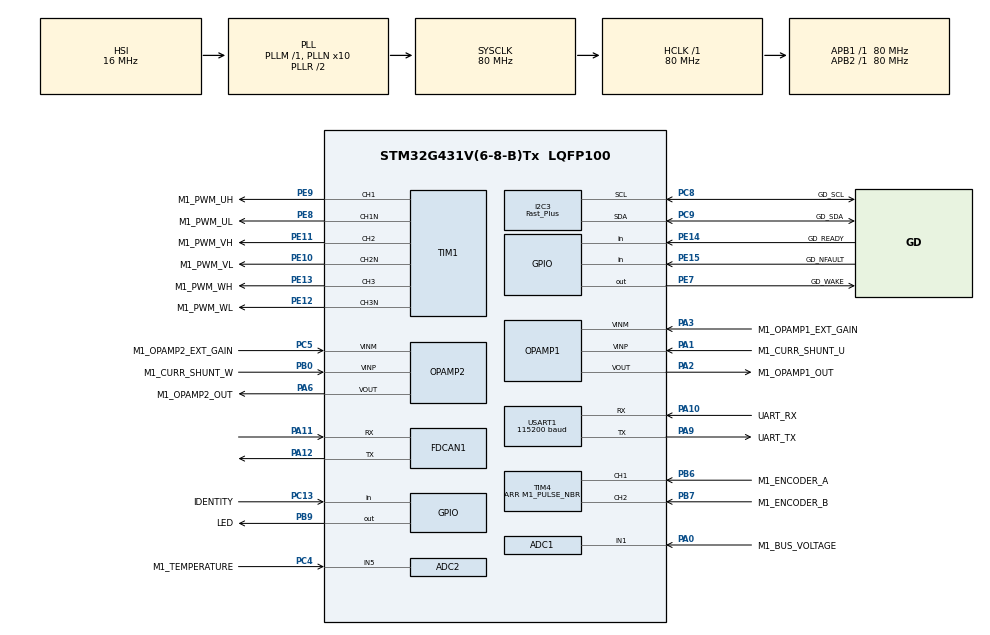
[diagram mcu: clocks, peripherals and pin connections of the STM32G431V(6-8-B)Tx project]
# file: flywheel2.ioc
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ADC1.Channel-1\#ChannelRegularConversion=ADC_CHANNEL_1
ADC1.ClockPrescaler=ADC_CLOCK_ASYNC_DIV1
ADC1.ContinuousConvMode=DISABLE
ADC1.DMAContinuousRequests=DISABLE
ADC1.DataAlign=ADC_DATAALIGN_LEFT
ADC1.DiscontinuousConvMode=DISABLE
ADC1.EOCSelection=ADC_EOC_SINGLE_CONV
ADC1.EnableAnalogWatchDog1=false
ADC1.EnableAnalogWatchDog2=false
ADC1.EnableAnalogWatchDog3=false
ADC1.EnableInjectedConversion=ENABLE
ADC1.EnableRegularConversion=ENABLE
ADC1.ExternalTrigConv=ADC_SOFTWARE_START
ADC1.ExternalTrigConvEdge=ADC_EXTERNALTRIGCONVEDGE_NONE
ADC1.ExternalTrigInjecConv=ADC_EXTERNALTRIGINJEC_T1_TRGO
ADC1.ExternalTrigInjecConvEdge=ADC_EXTERNALTRIGINJECCONV_EDGE_RISING
ADC1.InjNumberOfConversion=1
ADC1.InjectedChannel-1\#ChannelInjectedConversion=ADC_CHANNEL_3
ADC1.InjectedConvMode=None
ADC1.InjectedOffset-1\#ChannelInjectedConversion=0
ADC1.InjectedOffsetNumber-1\#ChannelInjectedConversion=ADC_OFFSET_NONE
ADC1.InjectedRank-1\#ChannelInjectedConversion=1
ADC1.InjectedSamplingTime-1\#ChannelInjectedConversion=ADC_SAMPLETIME_6CYCLES_5
ADC1.LowPowerAutoWait=DISABLE
ADC1.NbrOfConversion=1
ADC1.NbrOfConversionFlag=1
ADC1.Offset-1\#ChannelRegularConversion=0
ADC1.OffsetNumber-1\#ChannelRegularConversion=ADC_OFFSET_NONE
ADC1.Overrun=ADC_OVR_DATA_PRESERVED
ADC1.Rank-1\#ChannelRegularConversion=1
ADC1.Resolution=ADC_RESOLUTION_12B
ADC1.SamplingTime-1\#ChannelRegularConversion=ADC_SAMPLETIME_47CYCLES_5
ADC1.ScanConvMode=ADC_SCAN_DISABLE
ADC1.master=1
ADC2.Channel-1\#ChannelRegularConversion=ADC_CHANNEL_5
ADC2.ClockPrescaler=ADC_CLOCK_ASYNC_DIV1
ADC2.ContinuousConvMode=DISABLE
ADC2.DMAContinuousRequests=DISABLE
ADC2.DataAlign=ADC_DATAALIGN_LEFT
ADC2.DiscontinuousConvMode=DISABLE
ADC2.EOCSelection=ADC_EOC_SINGLE_CONV
ADC2.EnableAnalogWatchDog1=false
ADC2.EnableAnalogWatchDog2=false
ADC2.EnableAnalogWatchDog3=false
ADC2.EnableInjectedConversion=ENABLE
ADC2.EnableRegularConversion=ENABLE
ADC2.ExternalTrigConv=ADC_SOFTWARE_START
ADC2.ExternalTrigConvEdge=ADC_EXTERNALTRIGCONVEDGE_NONE
ADC2.ExternalTrigInjecConv=ADC_EXTERNALTRIGINJEC_T1_TRGO
ADC2.ExternalTrigInjecConvEdge=ADC_EXTERNALTRIGINJECCONV_EDGE_RISING
ADC2.InjNumberOfConversion=1
ADC2.InjectedChannel-1\#ChannelInjectedConversion=ADC_CHANNEL_3
ADC2.InjectedConvMode=None
ADC2.InjectedOffset-1\#ChannelInjectedConversion=0
ADC2.InjectedOffsetNumber-1\#ChannelInjectedConversion=ADC_OFFSET_NONE
ADC2.InjectedRank-1\#ChannelInjectedConversion=1
ADC2.InjectedSamplingTime-1\#ChannelInjectedConversion=ADC_SAMPLETIME_6CYCLES_5
ADC2.LowPowerAutoWait=DISABLE
ADC2.NbrOfConversion=1
ADC2.NbrOfConversionFlag=1
ADC2.Offset-1\#ChannelRegularConversion=0
ADC2.OffsetNumber-1\#ChannelRegularConversion=ADC_OFFSET_NONE
ADC2.Overrun=ADC_OVR_DATA_PRESERVED
ADC2.Rank-1\#ChannelRegularConversion=1
ADC2.Resolution=ADC_RESOLUTION_12B
ADC2.SamplingTime-1\#ChannelRegularConversion=ADC_SAMPLETIME_47CYCLES_5
ADC2.ScanConvMode=ADC_SCAN_DISABLE
ADC2.master=1
Dma.Request0=USART1_RX
Dma.Request1=USART1_TX
Dma.USART1_RX.0.Direction=DMA_PERIPH_TO_MEMORY
Dma.USART1_RX.0.EventEnable=DISABLE
Dma.USART1_RX.0.Instance=DMA1_Channel1
Dma.USART1_RX.0.MemDataAlignment=DMA_MDATAALIGN_BYTE
Dma.USART1_RX.0.MemInc=DMA_MINC_ENABLE
Dma.USART1_RX.0.Mode=DMA_NORMAL
Dma.USART1_RX.0.PeriphDataAlignment=DMA_PDATAALIGN_BYTE
Dma.USART1_RX.0.PeriphInc=DMA_PINC_DISABLE
Dma.USART1_RX.0.Polarity=HAL_DMAMUX_REQ_GEN_RISING
Dma.USART1_RX.0.Priority=DMA_PRIORITY_LOW
Dma.USART1_RX.0.RequestNumber=1
Dma.USART1_RX.0.SignalID=NONE
Dma.USART1_RX.0.SyncEnable=DISABLE
Dma.USART1_RX.0.SyncPolarity=HAL_DMAMUX_SYNC_NO_EVENT
Dma.USART1_RX.0.SyncRequestNumber=1
Dma.USART1_RX.0.SyncSignalID=NONE
Dma.USART1_TX.1.Direction=DMA_MEMORY_TO_PERIPH
Dma.USART1_TX.1.EventEnable=DISABLE
Dma.USART1_TX.1.Instance=DMA1_Channel2
Dma.USART1_TX.1.MemDataAlignment=DMA_MDATAALIGN_BYTE
Dma.USART1_TX.1.MemInc=DMA_MINC_ENABLE
Dma.USART1_TX.1.Mode=DMA_NORMAL
Dma.USART1_TX.1.PeriphDataAlignment=DMA_PDATAALIGN_BYTE
Dma.USART1_TX.1.PeriphInc=DMA_PINC_DISABLE
Dma.USART1_TX.1.Polarity=HAL_DMAMUX_REQ_GEN_RISING
Dma.USART1_TX.1.Priority=DMA_PRIORITY_LOW
Dma.USART1_TX.1.RequestNumber=1
Dma.USART1_TX.1.SignalID=NONE
Dma.USART1_TX.1.SyncEnable=DISABLE
Dma.USART1_TX.1.SyncPolarity=HAL_DMAMUX_SYNC_NO_EVENT
Dma.USART1_TX.1.SyncRequestNumber=1
Dma.USART1_TX.1.SyncSignalID=NONE
ExtraMW=MotorControl
ExtraMW.MotorControl.Config=MotorControl
ExtraMW.MotorControl.Mode=MotorControl
ExtraMW.MotorControl.Root=MCSDK_v6.4.1-Full/MotorControl
ExtraMW.MotorControl.Template=templates
FDCAN1.CalculateBaudRateNominal=1000000
FDCAN1.CalculateTimeBitNominal=1000
FDCAN1.CalculateTimeQuantumNominal=62.5
FDCAN1.NominalPrescaler=5
FDCAN1.NominalTimeSeg1=12
FDCAN1.NominalTimeSeg2=3
I2C3.I2C_Speed_Mode=I2C_Fast_Plus
I2C3.Timing=0x00B10E24
Mcu.Family=STM32G4
Mcu.Name=STM32G431V(6-8-B)Tx
Mcu.Package=LQFP100
MotorControl.ADC_1_PERIPH=ADC1
MotorControl.ADC_2_PERIPH=ADC2
MotorControl.ADC_AHBPERIPH=RCC_AHBPeriph_ADC12
MotorControl.ADC_CLOCK_WB_DIV=1
MotorControl.ADC_PERIPH=ADC1
MotorControl.ADC_REFERENCE_VOLTAGE=3.3
MotorControl.BOARD=Jame_driver_v2
MotorControl.BUS_VOLTAGE_READING=true
MotorControl.CCMRAM_ENABLED=false
MotorControl.CLOCK_FREQUENCY=CPU_CLK_170_MHZ
MotorControl.CLOCK_SOURCE=INTERNAL
MotorControl.CPU_CLK_170_MHZ=true
MotorControl.CTLBOARD_NAME=Jame_driver_v2
MotorControl.CUBE_MX_VER=6.16.1
MotorControl.CURRENT_READING_TOPOLOGY=THREE_SHUNT_INDEPENDENT_RESOURCES
MotorControl.CURR_SAMPLING_TIME=6
MotorControl.DBG_MCU_LOAD_MEASURE=false
MotorControl.DEBUG_DAC_FUNCTIONALITY_EN=false
MotorControl.DRIVES_NUMBER_SELECTION=SINGLEDRIVE
MotorControl.DRIVE_NUMBER=1
MotorControl.DRIVE_TYPE=FOC
MotorControl.ENCODER=true
MotorControl.ENCODER_AVAILABLE=true
MotorControl.ENCODER_PPR=1024
MotorControl.ENC_A_GPIO_PIN=LL_GPIO_PIN_6
MotorControl.ENC_A_GPIO_PORT=GPIOB
MotorControl.ENC_B_GPIO_PIN=LL_GPIO_PIN_7
MotorControl.ENC_B_GPIO_PORT=GPIOB
MotorControl.ENC_ICx_FILTER=119
MotorControl.ENC_INVERT_SPEED=true
MotorControl.ENC_TIMER_SELECTION=ENC_TIM4
MotorControl.ENC_USE_CH3=false
MotorControl.EXT_CLOCK_FREQUENCY=INT_RC_OSC
MotorControl.FEEDBACK_NET_FILTERING=false
MotorControl.FLASH_SIZE=128
MotorControl.HALL_SENSORS_AVAILABLE=false
MotorControl.HIGH_SIDE_IDLE_STATE=false
MotorControl.HWV_CS=ThreeShunt_RawCurrents_SingleEnded_ExternalGain
MotorControl.HWV_PWM=PoweringHighAndLowSides
MotorControl.HW_COMPLEMENTED_LOW_SIDE=false
MotorControl.HW_DEAD_TIME_NS=750
MotorControl.INT_RC_OSC=true
MotorControl.IPs=I2C3,CORDIC,SYS,NVIC,RCC,MotorControl,TIM1,OPAMP1,OPAMP2,ADC1,ADC2,TIM4,USART1,DMA
MotorControl.LOW_MEMORY_FOOTPRINT_REG=false
MotorControl.LOW_SIDE_IDLE_STATE=false
MotorControl.LOW_SIDE_SIGNALS_ENABLING=LS_PWM_TIMER
MotorControl.M1_ALIGNMENT_ANGLE_DEG=90
MotorControl.M1_ALIGNMENT_DURATION=1200
MotorControl.M1_AMPLIFICATION_GAIN=7.33
MotorControl.M1_ANGC={0,0,0,0,0,0,0,0}
MotorControl.M1_AUXILIARY_SPEED_SENSOR=NONE
MotorControl.M1_BOARD_MAX_CURRENT=43.3
MotorControl.M1_BUS_VOLTAGE_READING=true
MotorControl.M1_COMMUTATION_STEP_TIME_BUF_SIZE=12
MotorControl.M1_CONSTANT1_D=49154
MotorControl.M1_CONSTANT1_Q=49154
MotorControl.M1_CONSTANT2_QD=4907
MotorControl.M1_CS_ADC_NUM=2
MotorControl.M1_CS_ADC_PHASE_SHARED=NONE
MotorControl.M1_CS_ADC_U=ADC1
MotorControl.M1_CS_ADC_W=ADC2
MotorControl.M1_CS_CHANNEL_U=3
MotorControl.M1_CS_CHANNEL_W=3
MotorControl.M1_CS_OPAMP_DYNAMIC_OUTPUT_SWITCH=false
MotorControl.M1_CS_OPAMP_NUM=2
MotorControl.M1_CS_OPAMP_PHASE_SHARED=V
MotorControl.M1_CS_OPAMP_U=OPAMP1
MotorControl.M1_CS_OPAMP_VPSEL_U=PA1
MotorControl.M1_CS_OPAMP_VPSEL_V=PA7
MotorControl.M1_CS_OPAMP_VPSEL_W=PB0
MotorControl.M1_CS_OPAMP_W=OPAMP2
MotorControl.M1_CURRENT_AMPLIFICATION_TOPO=INT_SINGLE_ENDED
MotorControl.M1_CURRENT_SENSING_TOPO=THREE_SHUNT
MotorControl.M1_CURR_SAMPLING_TIME=6
MotorControl.M1_DBG_OPEN_LOOP_ENABLE=true
MotorControl.M1_DC_CURRENT_RS_MEAS=43.3
MotorControl.M1_DEFAULT_CONTROL_MODE=STC_SPEED_MODE
MotorControl.M1_DEFAULT_FLUX_COMPONENT=0
MotorControl.M1_DEFAULT_TARGET_SPEED_RPM=5400
MotorControl.M1_DEFAULT_TORQUE_COMPONENT=0
MotorControl.M1_DISCONTINUOUS_PWM=false
MotorControl.M1_DP_TOPOLOGY=NONE
MotorControl.M1_DRIVE_TYPE=FOC
MotorControl.M1_ENCODER_PPR=1024
MotorControl.M1_ENC_AVERAGING_FIFO_DEPTH=16
MotorControl.M1_ENC_A_GPIO_PIN=LL_GPIO_PIN_6
MotorControl.M1_ENC_A_GPIO_PORT=GPIOB
MotorControl.M1_ENC_B_GPIO_PIN=LL_GPIO_PIN_7
MotorControl.M1_ENC_B_GPIO_PORT=GPIOB
MotorControl.M1_ENC_ICx_FILTER=119
MotorControl.M1_ENC_TIMER_IRQ=TIM4
MotorControl.M1_ENC_TIMER_SELECTION=ENC_TIM4
MotorControl.M1_ENC_USE_CH3=false
MotorControl.M1_FEED_FORWARD_CURRENT_REG_ENABLING=false
MotorControl.M1_FINAL_I_ALIGNMENT=20
MotorControl.M1_FLUX_WEAKENING_ENABLING=false
MotorControl.M1_FW_KIDIV=32768
MotorControl.M1_FW_KI_GAIN=5000
MotorControl.M1_FW_KPDIV=32768
MotorControl.M1_FW_KP_GAIN=3000
MotorControl.M1_FW_VOLTAGE_REF=985
MotorControl.M1_HALL_PHASE_SHIFT=300
MotorControl.M1_HALL_SENSORS_PLACEMENT=DEGREES_120
MotorControl.M1_HIGH_SIDE_IDLE_STATE=false
MotorControl.M1_HW_DEAD_TIME_NS=750
MotorControl.M1_ICL_ENABLED=false
MotorControl.M1_ID_DEMAG=-43.3
MotorControl.M1_INT_AMP_OPAMP1_PIN=[{'mode'\:'Standalone','name'\:'PA1','signal'\:'OPAMP1_VINP','label'\:'SHUNT_P_U'},{'mode'\:'Standalone','name'\:'PA3','signal'\:'OPAMP1_VINM','label'\:'CURR_AMP_U'},{'mode'\:'Standalone','name'\:'PA2','signal'\:'OPAMP1_VOUT','label'\:'CURR_AMP_U'},{'mode'\:'Standalone','name'\:'PA7','signal'\:'OPAMP1_VINP','label'\:'SHUNT_P_V'},{'mode'\:'Standalone','name'\:'PC5','signal'\:'OPAMP1_VINM','label'\:'CURR_AMP_V'},{'mode'\:'Standalone','name'\:'PA2','signal'\:'OPAMP1_VOUT','label'\:'CURR_AMP_V'}]
MotorControl.M1_INT_AMP_OPAMP2_PIN=[{'mode'\:'Standalone','name'\:'PB0','signal'\:'OPAMP2_VINP','label'\:'SHUNT_P_W'},{'mode'\:'Standalone','name'\:'PC5','signal'\:'OPAMP2_VINM','label'\:'CURR_AMP_W'},{'mode'\:'Standalone','name'\:'PA6','signal'\:'OPAMP2_VOUT','label'\:'CURR_AMP_W'},{'mode'\:'Standalone','name'\:'PA7','signal'\:'OPAMP2_VINP','label'\:'SHUNT_P_V'},{'mode'\:'Standalone','name'\:'PC5','signal'\:'OPAMP2_VINM','label'\:'CURR_AMP_V'},{'mode'\:'Standalone','name'\:'PA6','signal'\:'OPAMP2_VOUT','label'\:'CURR_AMP_V'}]
MotorControl.M1_INT_AMP_OPAMPS=['OPAMP1','OPAMP2']
MotorControl.M1_IQMAX=43.3
MotorControl.M1_LDLQ_RATIO=1.000
MotorControl.M1_LOW_SIDE_IDLE_STATE=false
MotorControl.M1_LOW_SIDE_SIGNALS_ENABLING=LS_PWM_TIMER
MotorControl.M1_LS=0.00007
MotorControl.M1_MAX_APPLICATION_SPEED=15000
MotorControl.M1_MAX_MODULATION_INDEX=100
MotorControl.M1_MIN_APPLICATION_SPEED=0
MotorControl.M1_MOTOR_MAX_SPEED_RPM=15000
MotorControl.M1_MOTOR_NAME=ILM38x06 Star Parrellel
MotorControl.M1_MOTOR_RATED_FLUX=0.007908353
MotorControl.M1_MOTOR_VOLTAGE_CONSTANT=1.1
MotorControl.M1_MTPA_ENABLING=false
MotorControl.M1_NOMINAL_BUS_VOLTAGE_V=33
MotorControl.M1_NOMINAL_CURRENT=43.3
MotorControl.M1_OCP_TOPOLOGY=NONE
MotorControl.M1_OFST={0,0,0,0,0,0,0,0}
MotorControl.M1_ON_OVER_VOLTAGE=TURN_OFF_PWM
MotorControl.M1_OVERMODULATION=false
MotorControl.M1_OVP_THRESHOLD_HIGH=33
MotorControl.M1_OV_TEMPERATURE_PROT_ENABLING=false
MotorControl.M1_OV_VOLTAGE_PROT_ENABLING=true
MotorControl.M1_OV_VOLTAGE_THRESHOLD_V=33
MotorControl.M1_PID_FLUX_KD_DEFAULT=100
MotorControl.M1_PID_FLUX_KI_DEFAULT=754
MotorControl.M1_PID_FLUX_KP_DEFAULT=2347
MotorControl.M1_PID_SPEED_KD_DEFAULT=0
MotorControl.M1_PID_SPEED_KI_DEFAULT=52
MotorControl.M1_PID_SPEED_KP_DEFAULT=3646
MotorControl.M1_PID_TORQUE_KD_DEFAULT=100
MotorControl.M1_PID_TORQUE_KI_DEFAULT=754
MotorControl.M1_PID_TORQUE_KP_DEFAULT=2347
MotorControl.M1_POLE_PAIR_NUM=7
MotorControl.M1_POSITION_CTRL_ENABLING=false
MotorControl.M1_POTENTIOMETER_ENABLE=false
MotorControl.M1_POWERBOARD_NAME=Jame_driver_v2
MotorControl.M1_PWM_CHARGE_BOOT_CAP_DUTY_CYCLES=0.000
MotorControl.M1_PWM_CHARGE_BOOT_CAP_MS=10
MotorControl.M1_PWM_DRIVER_PN=NTMFSC1D0N04HL
MotorControl.M1_PWM_FREQUENCY=16000
MotorControl.M1_PWM_TIMER_BRK_IRQ=TIM1_BRK_TIM15
MotorControl.M1_PWM_TIMER_SELECTION=PWM_TIM1
MotorControl.M1_PWM_TIMER_UP_IRQ=TIM1_UP_TIM16
MotorControl.M1_REGULATION_EXECUTION_RATE=1
MotorControl.M1_RS=0.09
MotorControl.M1_RSHUNT=0.01
MotorControl.M1_SEGDIV=0
MotorControl.M1_SHARED_SIGNAL_ENABLE=false
MotorControl.M1_SPD_DIFFERENTIAL_TERM_ENABLING=false
MotorControl.M1_SPEED_LOOP_FREQUENCY_HZ=1000
MotorControl.M1_SPEED_SENSOR=QUAD_ENCODER
MotorControl.M1_SP_KDDIV=16
MotorControl.M1_SP_KIDIV=16384
MotorControl.M1_SP_KPDIV=1024
MotorControl.M1_SS_MEAS_ERRORS_BEFORE_FAULTS=3
MotorControl.M1_SW_DEADTIME_NS=575
MotorControl.M1_T0_C=50
MotorControl.M1_TEMPERATURE_READING=true
MotorControl.M1_TEMP_ADC_SAMPLING_TIME=47
MotorControl.M1_TEMP_FDBK_ADC=ADC2
MotorControl.M1_TEMP_FDBK_CHANNEL=ADC_CHANNEL_5
MotorControl.M1_TF_KDDIV=8192
MotorControl.M1_TF_KIDIV=16384
MotorControl.M1_TF_KPDIV=4096
MotorControl.M1_TNOISE_NS=150
MotorControl.M1_TRISE_NS=61
MotorControl.M1_T_MAX=100
MotorControl.M1_UD_VOLTAGE_THRESHOLD_V=1
MotorControl.M1_USE_INTERNAL_OPAMP=true
MotorControl.M1_UV_VOLTAGE_PROT_ENABLING=true
MotorControl.M1_V0_V=1.75
MotorControl.M1_VBUS_ADC=ADC1
MotorControl.M1_VBUS_ADC_SAMPLING_TIME=47
MotorControl.M1_VBUS_CHANNEL=ADC_CHANNEL_1
MotorControl.M1_VBUS_PARTITIONING_FACTOR=0.0625
MotorControl.M1_dV_dT=0.025
MotorControl.MAX_READABLE_CURRENT=22.51
MotorControl.MCPA_OVER_UART_A_STREAM=10
MotorControl.MCP_ASPEP_OVER_UART=true
MotorControl.MCP_ASYNC_EN=true
MotorControl.MCP_ASYNC_OVER_ASPEP_EN=true
MotorControl.MCP_ASYNC_OVER_UART_A_EN=true
MotorControl.MCP_DMACH_RX_UART_A=1
MotorControl.MCP_DMACH_TX_UART_A=2
MotorControl.MCP_DMA_RX_UART_A=DMA1
MotorControl.MCP_DMA_TX_UART_A=DMA1
MotorControl.MCP_EN=true
MotorControl.MCP_IRQ_HANDLER_DMA_RX_UART_A=DMA1_Channel1_IRQHandler
MotorControl.MCP_IRQ_HANDLER_UART_A=USART1_IRQHandler
MotorControl.MCP_OVER_ASPEP_EN=true
MotorControl.MCP_OVER_STLNK_EN=false
MotorControl.MCP_OVER_UART_A_EN=true
MotorControl.MCP_OVER_UART_B_EN=false
MotorControl.MCP_RX_SYNC_PAYLOAD_MAX=256
MotorControl.MCP_TX_ASYNC_PAYLOAD_MAX_UART_A=2048
MotorControl.MCP_TX_SYNC_PAYLOAD_MAX=256
MotorControl.MCU=STSPIN32G4
MotorControl.MCU_FAMILY=STM32G4
MotorControl.MCU_LINE=STM32G4x1
MotorControl.MCU_NAME=STM32G431V(6-8-B)Tx
MotorControl.MCU_PACKAGE=LQFP100
MotorControl.MCU_TYPE=STSPIN32G4
MotorControl.MCU_USERNAME=STM32G431VBTx
MotorControl.MC_WORKBENCH_VERSION=6.4.1
MotorControl.MOTOR_PROFILER=false
MotorControl.MOTOR_TYPE=PMSM
MotorControl.ON_OVER_VOLTAGE=TURN_OFF_PWM
MotorControl.OPAMP1_INVERTINGINPUT=OPAMP1_InvertingInput_PA3
MotorControl.OPAMP1_INVERTINGINPUT_GPIO_PIN=LL_GPIO_PIN_3
MotorControl.OPAMP1_INVERTINGINPUT_GPIO_PORT=GPIOA
MotorControl.OPAMP1_INVERTINGINPUT_MODE=EXT_MODE
MotorControl.OPAMP1_NONINVERTINGINPUT_PHA=OPAMP1_NonInvertingInput_PA1
MotorControl.OPAMP1_NONINVERTINGINPUT_PHA_GPIO_PIN=LL_GPIO_PIN_1
MotorControl.OPAMP1_NONINVERTINGINPUT_PHA_GPIO_PORT=GPIOA
MotorControl.OPAMP1_NONINVERTINGINPUT_PHB=OPAMP1_NonInvertingInput_PA7
MotorControl.OPAMP1_NONINVERTINGINPUT_PHB_GPIO_PIN=LL_GPIO_PIN_7
MotorControl.OPAMP1_NONINVERTINGINPUT_PHB_GPIO_PORT=GPIOA
MotorControl.OPAMP1_OUT_GPIO_PIN=LL_GPIO_PIN_2
MotorControl.OPAMP1_OUT_GPIO_PORT=GPIOA
MotorControl.OPAMP1_SELECTION=OPAMP1
MotorControl.OPAMP2_INVERTINGINPUT=OPAMP2_InvertingInput_PC5
MotorControl.OPAMP2_INVERTINGINPUT_GPIO_PIN=LL_GPIO_PIN_5
MotorControl.OPAMP2_INVERTINGINPUT_GPIO_PORT=GPIOC
MotorControl.OPAMP2_INVERTINGINPUT_MODE=EXT_MODE
MotorControl.OPAMP2_NONINVERTINGINPUT_PHB=OPAMP2_NonInvertingInput_PA7
MotorControl.OPAMP2_NONINVERTINGINPUT_PHB_GPIO_PIN=LL_GPIO_PIN_7
MotorControl.OPAMP2_NONINVERTINGINPUT_PHB_GPIO_PORT=GPIOA
MotorControl.OPAMP2_NONINVERTINGINPUT_PHC=OPAMP2_NonInvertingInput_PB0
MotorControl.OPAMP2_NONINVERTINGINPUT_PHC_GPIO_PIN=LL_GPIO_PIN_0
MotorControl.OPAMP2_NONINVERTINGINPUT_PHC_GPIO_PORT=GPIOB
MotorControl.OPAMP2_OUT_GPIO_PIN=LL_GPIO_PIN_6
MotorControl.OPAMP2_OUT_GPIO_PORT=GPIOA
MotorControl.OPAMP2_SELECTION=OPAMP2
MotorControl.OPAMP_PGAGAIN=OPAMP_OPAMP_PGAGain_16
MotorControl.OPAMP_TYPE_GAIN=EXTERNAL
MotorControl.OV_TEMPERATURE_PROT_ENABLING=false
MotorControl.OV_VOLTAGE_PROT_ENABLING=true
MotorControl.PHASE_UH_GPIO_PIN=LL_GPIO_PIN_9
MotorControl.PHASE_UH_GPIO_PORT=GPIOE
MotorControl.PHASE_UH_POLARITY=H_ACTIVE_HIGH
MotorControl.PHASE_UL_GPIO_PIN=LL_GPIO_PIN_8
MotorControl.PHASE_UL_GPIO_PORT=GPIOE
MotorControl.PHASE_UL_POLARITY=L_ACTIVE_HIGH
MotorControl.PHASE_U_CURR_ADC=ADC1
MotorControl.PHASE_U_CURR_CHANNEL=ADC_CHANNEL_3
MotorControl.PHASE_U_GPIO_PIN=LL_GPIO_PIN_2
MotorControl.PHASE_U_GPIO_PORT=GPIOA
MotorControl.PHASE_U_PWM_CHANNEL=TIM_Channel_1
MotorControl.PHASE_VH_GPIO_PIN=LL_GPIO_PIN_11
MotorControl.PHASE_VH_GPIO_PORT=GPIOE
MotorControl.PHASE_VH_POLARITY=H_ACTIVE_HIGH
MotorControl.PHASE_VL_GPIO_PIN=LL_GPIO_PIN_10
MotorControl.PHASE_VL_GPIO_PORT=GPIOE
MotorControl.PHASE_VL_POLARITY=L_ACTIVE_HIGH
MotorControl.PHASE_V_CURR_ADC=ADC2
MotorControl.PHASE_V_CURR_CHANNEL=ADC_CHANNEL_3
MotorControl.PHASE_V_GPIO_PIN=LL_GPIO_PIN_6
MotorControl.PHASE_V_GPIO_PORT=GPIOA
MotorControl.PHASE_V_PWM_CHANNEL=TIM_Channel_2
MotorControl.PHASE_WH_GPIO_PIN=LL_GPIO_PIN_13
MotorControl.PHASE_WH_GPIO_PORT=GPIOE
MotorControl.PHASE_WH_POLARITY=H_ACTIVE_HIGH
MotorControl.PHASE_WL_GPIO_PIN=LL_GPIO_PIN_12
MotorControl.PHASE_WL_GPIO_PORT=GPIOE
MotorControl.PHASE_WL_POLARITY=L_ACTIVE_HIGH
MotorControl.PHASE_W_PWM_CHANNEL=TIM_Channel_3
MotorControl.POTENTIOMETER_READING=false
MotorControl.PWM_FREQUENCY=16000
MotorControl.PWM_TIMER_SELECTION=PWM_TIM1
MotorControl.REGULATION_EXECUTION_RATE=1
MotorControl.RTOS=NONE
MotorControl.R_BRAKE_SWITCH_OFF_THRES_V=26
MotorControl.SINGLEDRIVE=true
MotorControl.SPD_DIFFERENTIAL_TERM_ENABLING=false
MotorControl.SPEED_SENSOR_SELECTION=ENCODER
MotorControl.START_STOP_BTN=false
MotorControl.STSPIN32G4=true
MotorControl.SW_DEADTIME_NS=575
MotorControl.TEMPERATURE_READING=true
MotorControl.TEMP_ADC_SAMPLING_TIME=47
MotorControl.TEMP_FDBK_ADC=ADC2
MotorControl.TEMP_FDBK_CHANNEL=ADC_CHANNEL_5
MotorControl.TEMP_FDBK_GPIO_PIN=LL_GPIO_PIN_4
MotorControl.TEMP_FDBK_GPIO_PORT=GPIOC
MotorControl.TFDIFFERENTIAL_TERM_ENABLING=false
MotorControl.THREE_SHUNT_INDEPENDENT_RESOURCES=true
MotorControl.TRISE_NS=61
MotorControl.USART_RX_GPIO_PIN=LL_GPIO_PIN_10
MotorControl.USART_RX_GPIO_PORT=GPIOA
MotorControl.USART_SELECTION=USE_USART1
MotorControl.USART_SELECTION_A=USART1
MotorControl.USART_SPEED=1843200
MotorControl.USART_TX_GPIO_PIN=LL_GPIO_PIN_9
MotorControl.USART_TX_GPIO_PORT=GPIOA
MotorControl.USE_3OPAMPS=false
MotorControl.USE_INTERNAL_OPAMP=true
MotorControl.UV_VOLTAGE_PROT_ENABLING=true
MotorControl.VBUS_ADC=ADC1
MotorControl.VBUS_ADC_SAMPLING_TIME=47
MotorControl.VBUS_CHANNEL=ADC_CHANNEL_1
MotorControl.VBUS_GPIO_PIN=LL_GPIO_PIN_0
MotorControl.VBUS_GPIO_PORT=GPIOA
MotorControl.WB_MX_HEAPSIZE=0x200
MotorControl.WB_MX_STACKSIZE=0x400
MotorControl.WB_MX_TRUSTZONE_AVAILABLE=false
MotorControl.WB_UI_CUTOFF_FREQUENCY=6000
MotorControl.WB_UI_ENCODER_HAS_INDEX_PIN=true
MotorControl.WB_UI_FLUX_TARGET=0
MotorControl.WB_UI_FRICTION=0.49
MotorControl.WB_UI_GON=0.88
MotorControl.WB_UI_GOP=8.333
MotorControl.WB_UI_INERTIA=0.55
MotorControl.WB_UI_MAGNETIC_STRUCTURE=SM-PMSM
MotorControl.WB_UI_MAX_CURRENT=43.3
MotorControl.WB_UI_MAX_NOMINAL_DC_VOLTAGE=48
MotorControl.WB_UI_MAX_PWMFREQUENCY=40000
MotorControl.WB_UI_PW_BOARD_MAX_RATED_CURRENT=45
MotorControl.WB_UI_PW_BOARD_MAX_VOLTAGE=33
MotorControl.WB_UI_PW_BOARD_MIN_VOLTAGE=1
MotorControl.WB_UI_VPOL=1.65
MotorControl.WB_UI_VPOL_K=0.1980079203
MotorControl.WB_to_Mx_template_version=25-05-06
MotorControl.WB_to_Mx_version=6.4.1-RC1-Full
NVIC.ADC1_2_IRQn=true\:2\:0\:true\:true\:false\:5\:true\:true\:true
NVIC.DMA1_Channel1_IRQn=true\:3\:0\:true\:true\:false\:2\:true\:true\:true
NVIC.FDCAN1_IT0_IRQn=true\:0\:0\:false\:false\:true\:true\:true\:true
NVIC.FDCAN1_IT1_IRQn=true\:0\:0\:false\:false\:true\:true\:true\:true
NVIC.PriorityGroup=NVIC_PRIORITYGROUP_3
NVIC.TIM1_BRK_TIM15_IRQn=true\:4\:1\:true\:true\:false\:3\:true\:true\:true
NVIC.TIM1_UP_TIM16_IRQn=true\:0\:0\:false\:true\:false\:4\:true\:true\:true
NVIC.TIM4_IRQn=true\:3\:0\:false\:true\:false\:6\:true\:true\:true
NVIC.USART1_IRQn=true\:3\:1\:true\:true\:false\:1\:true\:true\:true
OPAMP1.SelfCalibration=Disable
OPAMP2.SelfCalibration=Disable
PA0.GPIO_Label=M1_BUS_VOLTAGE
PA0.Mode=IN1-Single-Ended
PA0.Signal=ADC1_IN1
PA1.GPIO_Label=M1_CURR_SHUNT_U
PA1.Mode=Standalone
PA1.Signal=OPAMP1_VINP
PA10.GPIO_Label=UART_RX
PA10.GPIO_Mode=GPIO_MODE_AF_PP
PA10.GPIO_PuPd=GPIO_NOPULL
PA10.GPIO_Speed=GPIO_SPEED_FREQ_LOW
PA10.Mode=Asynchronous
PA10.Signal=USART1_RX
PA11.Mode=FDCAN_Activate
PA11.Signal=FDCAN1_RX
PA12.Mode=FDCAN_Activate
PA12.Signal=FDCAN1_TX
PA13.GPIO_Label=TMS
PA13.Mode=Serial_Wire
PA13.Signal=SYS_JTMS-SWDIO
PA14.GPIO_Label=TCK
PA14.Mode=Serial_Wire
PA14.Signal=SYS_JTCK-SWCLK
PA2.GPIO_Label=M1_OPAMP1_OUT
PA2.Signal=SharedAnalog_PA2
PA3.GPIO_Label=M1_OPAMP1_EXT_GAIN
PA3.Mode=Standalone
PA3.Signal=OPAMP1_VINM
PA6.GPIO_Label=M1_OPAMP2_OUT
PA6.Signal=SharedAnalog_PA6
PA7.GPIO_Label=M1_CURR_SHUNT_V
PA7.Signal=OPAMP2_VINP_SEC
PA9.GPIO_Label=UART_TX
PA9.GPIO_Mode=GPIO_MODE_AF_PP
PA9.GPIO_PuPd=GPIO_NOPULL
PA9.GPIO_Speed=GPIO_SPEED_FREQ_LOW
PA9.Mode=Asynchronous
PA9.Signal=USART1_TX
PB0.GPIO_Label=M1_CURR_SHUNT_W
PB0.Mode=Standalone
PB0.Signal=OPAMP2_VINP
PB6.GPIO_Label=M1_ENCODER_A
PB6.Signal=S_TIM4_CH1
PB7.GPIO_Label=M1_ENCODER_B
PB7.Signal=S_TIM4_CH2
PB9.GPIO_Label=LED
PB9.Signal=GPIO_Output
PC13.GPIO_Label=IDENTITY
PC13.GPIO_PuPd=GPIO_PULLUP
PC13.Signal=GPIO_Input
PC4.GPIO_Label=M1_TEMPERATURE
PC4.Mode=IN5-Single-Ended
PC4.Signal=ADC2_IN5
PC5.GPIO_Label=M1_OPAMP2_EXT_GAIN
PC5.Mode=Standalone
PC5.Signal=OPAMP2_VINM
PC8.GPIO_Label=GD_SCL
PC8.Mode=I2C
PC8.Signal=I2C3_SCL
PC9.GPIO_Label=GD_SDA
PC9.Mode=I2C
PC9.Signal=I2C3_SDA
PE10.GPIO_Label=M1_PWM_VL
PE10.GPIO_PuPd=GPIO_PULLDOWN
PE10.GPIO_Speed=GPIO_SPEED_FREQ_HIGH
PE10.Mode=PWM Generation2 CH2 CH2N
PE10.Signal=TIM1_CH2N
PE11.GPIO_Label=M1_PWM_VH
PE11.GPIO_PuPd=GPIO_PULLDOWN
PE11.GPIO_Speed=GPIO_SPEED_FREQ_HIGH
PE11.Signal=S_TIM1_CH2
PE12.GPIO_Label=M1_PWM_WL
PE12.GPIO_PuPd=GPIO_PULLDOWN
PE12.GPIO_Speed=GPIO_SPEED_FREQ_HIGH
PE12.Mode=PWM Generation3 CH3 CH3N
PE12.Signal=TIM1_CH3N
PE13.GPIO_Label=M1_PWM_WH
PE13.GPIO_PuPd=GPIO_PULLDOWN
PE13.GPIO_Speed=GPIO_SPEED_FREQ_HIGH
PE13.Signal=S_TIM1_CH3
PE14.GPIO_Label=GD_READY
PE14.GPIO_PuPd=GPIO_PULLUP
PE14.Signal=GPIO_Input
PE15.GPIO_Label=GD_NFAULT
PE15.GPIO_PuPd=GPIO_PULLUP
PE15.Signal=GPIO_Input
PE7.GPIO_Label=GD_WAKE
PE7.PinState=GPIO_PIN_SET
PE7.Signal=GPIO_Output
PE8.GPIO_Label=M1_PWM_UL
PE8.GPIO_PuPd=GPIO_PULLDOWN
PE8.GPIO_Speed=GPIO_SPEED_FREQ_HIGH
PE8.Mode=PWM Generation1 CH1 CH1N
PE8.Signal=TIM1_CH1N
PE9.GPIO_Label=M1_PWM_UH
PE9.GPIO_PuPd=GPIO_PULLDOWN
PE9.GPIO_Speed=GPIO_SPEED_FREQ_HIGH
PE9.Signal=S_TIM1_CH1
ProjectManager.HeapSize=0x200
ProjectManager.StackSize=0x400
ProjectManager.TargetToolchain=STM32CubeIDE
RCC.ADC12CLockSelection=RCC_ADC12CLKSOURCE_PLL
RCC.ADC12Freq_Value=40000000
RCC.AHBFreq_Value=80000000
RCC.APB1Freq_Value=80000000
RCC.APB1TimFreq_Value=80000000
RCC.APB2Freq_Value=80000000
RCC.APB2TimFreq_Value=80000000
RCC.CK48CLockSelection=RCC_USBCLKSOURCE_PLL
RCC.CortexFreq_Value=80000000
RCC.EXTERNAL_CLOCK_VALUE=12288000
RCC.HCLKFreq_Value=80000000
RCC.HSE_VALUE=8000000
RCC.HSI48_VALUE=48000000
RCC.HSI_VALUE=16000000
RCC.LSE_VALUE=32768
RCC.PLLN=10
RCC.PLLP=RCC_PLLP_DIV4
RCC.PREFETCH_ENABLE=1
RCC.SYSCLKFreq_VALUE=80000000
RCC.SYSCLKSource=RCC_SYSCLKSOURCE_PLLCLK
RCC.USBFreq_Value=80000000
RCC.VCOOutputFreq_Value=160000000
SH.S_TIM1_CH1.0=TIM1_CH1,PWM Generation1 CH1 CH1N
SH.S_TIM1_CH2.0=TIM1_CH2,PWM Generation2 CH2 CH2N
SH.S_TIM1_CH3.0=TIM1_CH3,PWM Generation3 CH3 CH3N
SH.S_TIM4_CH1.0=TIM4_CH1,Encoder_Interface
SH.S_TIM4_CH2.0=TIM4_CH2,Encoder_Interface
SH.SharedAnalog_PA2.0=OPAMP1_VOUT,Standalone
SH.SharedAnalog_PA2.1=ADC1_IN3,IN3-Single-Ended
SH.SharedAnalog_PA6.0=OPAMP2_VOUT,Standalone
SH.SharedAnalog_PA6.1=ADC2_IN3,IN3-Single-Ended
TIM1.AutoReloadPreload=TIM_AUTORELOAD_PRELOAD_DISABLE
TIM1.AutomaticOutput=TIM_AUTOMATICOUTPUT_DISABLE
TIM1.Break2Filter=3
TIM1.Break2Polarity=TIM_BREAK2POLARITY_HIGH
TIM1.Break2State=TIM_BREAK2_DISABLE
TIM1.BreakFilter=0
TIM1.BreakPolarity=TIM_BREAKPOLARITY_HIGH
TIM1.BreakState=TIM_BREAK_DISABLE
TIM1.Channel=TIM_CHANNEL_4
TIM1.Channel-PWM\ Generation1\ CH1\ CH1N=TIM_CHANNEL_1
TIM1.Channel-PWM\ Generation2\ CH2\ CH2N=TIM_CHANNEL_2
TIM1.Channel-PWM\ Generation3\ CH3\ CH3N=TIM_CHANNEL_3
TIM1.Channel-PWM\ Generation4\ No\ Output=TIM_CHANNEL_4
TIM1.ClearInputSource=TIM_CLEARINPUTSOURCE_NONE
TIM1.ClockDivision=TIM_CLOCKDIVISION_DIV2
TIM1.CounterMode=TIM_COUNTERMODE_CENTERALIGNED1
TIM1.DeadTime=((DEAD_TIME_COUNTS) / 2)
TIM1.LockLevel=TIM_LOCKLEVEL_OFF
TIM1.OC1Preload_PWM=ENABLE
TIM1.OC2Preload_PWM=ENABLE
TIM1.OC3Preload_PWM=ENABLE
TIM1.OC4Preload_PWM=ENABLE
TIM1.OCFastMode_PWM=TIM_OCFAST_DISABLE
TIM1.OCIdleState_1=TIM_OCIDLESTATE_RESET
TIM1.OCIdleState_2=TIM_OCIDLESTATE_RESET
TIM1.OCIdleState_3=TIM_OCIDLESTATE_RESET
TIM1.OCIdleState_4=TIM_OCIDLESTATE_RESET
TIM1.OCMode_PWM-PWM\ Generation1\ CH1\ CH1N=TIM_OCMODE_PWM1
TIM1.OCMode_PWM-PWM\ Generation2\ CH2\ CH2N=TIM_OCMODE_PWM1
TIM1.OCMode_PWM-PWM\ Generation3\ CH3\ CH3N=TIM_OCMODE_PWM1
TIM1.OCMode_PWM-PWM\ Generation4\ No\ Output=TIM_OCMODE_PWM2
TIM1.OCNIdleState_1=TIM_OCNIDLESTATE_RESET
TIM1.OCNIdleState_2=TIM_OCNIDLESTATE_RESET
TIM1.OCNIdleState_3=TIM_OCNIDLESTATE_RESET
TIM1.OCNPolarity_1=TIM_OCNPOLARITY_HIGH
TIM1.OCNPolarity_2=TIM_OCNPOLARITY_HIGH
TIM1.OCNPolarity_3=TIM_OCNPOLARITY_HIGH
TIM1.OCPolarity_1=TIM_OCPOLARITY_HIGH
TIM1.OCPolarity_2=TIM_OCPOLARITY_HIGH
TIM1.OCPolarity_3=TIM_OCPOLARITY_HIGH
TIM1.OCPolarity_4=TIM_OCPOLARITY_HIGH
TIM1.OffStateIDLEMode=TIM_OSSI_ENABLE
TIM1.OffStateRunMode=TIM_OSSR_ENABLE
TIM1.PeriodNoDither=((PWM_PERIOD_CYCLES) / 2)
TIM1.Prescaler=((TIM_CLOCK_DIVIDER) - 1)
TIM1.PulseNoDither_1=((PWM_PERIOD_CYCLES) / 4)
TIM1.PulseNoDither_2=((PWM_PERIOD_CYCLES) / 4)
TIM1.PulseNoDither_3=((PWM_PERIOD_CYCLES) / 4)
TIM1.PulseNoDither_4=(((PWM_PERIOD_CYCLES) / 2) - (HTMIN))
TIM1.RepetitionCounter=(REP_COUNTER)
TIM1.SourceBRK2DigInput=TIM_BREAKINPUTSOURCE_DISABLE
TIM1.SourceBRKDigInput=TIM_BREAKINPUTSOURCE_DISABLE
TIM1.TIM_MasterOutputTrigger=TIM_TRGO_OC4REF
TIM1.TIM_MasterOutputTrigger2=TIM_TRGO2_RESET
TIM1.TIM_MasterSlaveMode=TIM_MASTERSLAVEMODE_DISABLE
TIM1.TIM_SlaveMode=TIM_SLAVEMODE_TRIGGER
TIM4.EncoderMode=TIM_ENCODERMODE_TI12
TIM4.IC1Filter=M1_ENC_IC_FILTER
TIM4.IC1Polarity=TIM_ICPOLARITY_RISING
TIM4.IC2Filter=M1_ENC_IC_FILTER
TIM4.IC2Polarity=TIM_ICPOLARITY_FALLING
TIM4.PeriodNoDither=M1_PULSE_NBR
USART1.BaudRate=115200
USART1.VirtualMode-Asynchronous=VM_ASYNC
USART1.WordLength=WORDLENGTH_8B
VP_CORDIC_VS_CORDIC.Mode=CORDIC_Activate
VP_MotorControl_MC_ENABLED.Mode=Enabled
VP_SYS_VS_DBSignals.Mode=DisableDeadBatterySignals
VP_TIM1_VS_no_output4.Mode=PWM Generation4 No Output
board=custom

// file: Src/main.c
/* USER CODE BEGIN Header */
/**
  ******************************************************************************
  * @file           : main.c
  * @brief          : Main program body
  ******************************************************************************
  * @attention
  *
  * Copyright (c) 2026 STMicroelectronics.
  * All rights reserved.
  *
  * This software is licensed under terms that can be found in the LICENSE file
  * in the root directory of this software component.
  * If no LICENSE file comes with this software, it is provided AS-IS.
  *
  ******************************************************************************
  */
/* USER CODE END Header */
#include "main.h"

/* USER CODE BEGIN Includes */
#include <stdio.h>
#include <stdint.h>
#include "mc_api.h"
/* Header includes required for MC definitions */
#include "mc_api.h"
#include "mc_config.h"
#include "mc_type.h"
/* USER CODE END Includes */

/* USER CODE BEGIN PTD */
typedef struct {
    float position_target; // Rad
    float velocity_target; // Rad/s
    float kp;              // Nm/Rad
    float kd;              // Nm/(Rad/s)
    float torque_ff;       // Nm
} CAN_Command_t;

typedef struct {
    float position_actual;
    float velocity_actual;
    float torque_actual;
    uint8_t motor_id;
    uint8_t error_code;
} CAN_Feedback_t;

// Definition for the real-time tracking interpolation structure
typedef struct {
    float position_target;
    float velocity_target;
    float torque_target;
    float kp;
    float kd;

    float position_curr;
    float velocity_curr;
    float torque_curr;

    float position_step;
    float velocity_step;
    float torque_step;

    uint16_t steps_per_can_frame;
    uint16_t interpolation_counter;
} ImpedanceController_t;
/* USER CODE END PTD */

/* USER CODE BEGIN PD */
#define MOTOR_KT          0.0095f     // [Nm/A] - torque constant
//#define IQMAX_A           20.0f       // [A]  - must match IQMAX_A in drive_parameters.h
#define TORQUE_MAX_NM     0.5f        // [Nm] - peak torque headroom (> IQMAX_A*KT = 0.19 Nm steady-state)

/* TEMPORARY bench test: set to 0 before restoring normal CAN torque control. */
#define TEMP_TORQUE_RAMP_TEST_ENABLE  0U
#define TEMP_TORQUE_TEST_NM           0.02f
#define TEMP_TORQUE_RAMP_MS           1000U
#define TEMP_TORQUE_HOLD_MS           2000U

/* Encoder velocity sign: set to +1.0f or -1.0f.
 * Test: spin motor by hand in positive direction (same as commanded).
 * Check velocity feedback in CAN response:
 *   - If positive  → keep  +1.0f
 *   - If negative  → change to -1.0f  (kd will runaway without this)
 * Tuning note: with pos_actual in radians (-π..+π), use kp in range 50–500 Nm/rad. */
#define ENCODER_VEL_SIGN 1.0f

// Conversion constants
#define DPP_TO_RADIANS (2.0f * 3.14159265f / 65536.0f)
#define RPM_TO_RADS    0.104719755f
#define M_PI  3.1415926

// Conversion constant: ST SDK electrical angle is usually an s16 mapping from -32768 to 32767
#define S16_TO_RADIANS    (3.14159265f / 32768.0f)
// 65536 total steps across 2*PI radians
#define DPP_TO_RADIANS (2.0f * 3.14159265f / 65536.0f)
/* USER CODE END PD */

ADC_HandleTypeDef hadc1;
ADC_HandleTypeDef hadc2;

CORDIC_HandleTypeDef hcordic;

FDCAN_HandleTypeDef hfdcan1;

I2C_HandleTypeDef hi2c3;

OPAMP_HandleTypeDef hopamp1;
OPAMP_HandleTypeDef hopamp2;

TIM_HandleTypeDef htim1;
TIM_HandleTypeDef htim4;

UART_HandleTypeDef huart1;
DMA_HandleTypeDef hdma_usart1_rx;
DMA_HandleTypeDef hdma_usart1_tx;

/* USER CODE BEGIN PV */
CAN_Command_t         IncomingCmd  = {0};
CAN_Feedback_t        CurrentState = {0};
ImpedanceController_t ImpedanceCtrl = {0};

volatile uint32_t can_rx_count = 0;
volatile uint8_t  force_align  = 0; /* set by CAN CMD_FORCE_ALIGN; handled in main loop */

/* Motor ID detected at startup from IDENTITY pin (PC13):
 *   PC13 floating (pulled high) → ID 0x01
 *   PC13 shorted to GND         → ID 0x02
 * g_ctrl_id is the state-machine command address = motor_id + 0x200 */
uint8_t  g_motor_id = 0x01;
uint32_t g_ctrl_id  = 0x201;

// Control command bytes (1-byte payload on CTRL_ID)
#define CMD_MOTOR_START  0x01
#define CMD_MOTOR_STOP   0x02
#define CMD_FEEDBACK_REQUEST 0x04
#define CMD_FORCE_ALIGN  0x03  /* stop → clear encoder alignment → restart */

// Motor parameters
#define MOTOR_POLE_PAIRS  POLE_PAIR_NUM  // [Pole Pairs] - pulled from pmsm_motor_parameters.h

/* USER CODE END PV */

void SystemClock_Config(void);
static void MX_GPIO_Init(void);
static void MX_DMA_Init(void);
static void MX_ADC1_Init(void);
static void MX_ADC2_Init(void);
static void MX_CORDIC_Init(void);
static void MX_I2C3_Init(void);
static void MX_OPAMP1_Init(void);
static void MX_OPAMP2_Init(void);
static void MX_TIM1_Init(void);
static void MX_TIM4_Init(void);
static void MX_USART1_UART_Init(void);
static void MX_FDCAN1_Init(void);
static void MX_NVIC_Init(void);
/* USER CODE BEGIN PFP */
void CAN_Interrupt_Init(void);
float Math_Map_Int_To_Float(int x_int, float x_min, float x_max, int bits);
int Math_Map_Float_To_Int(float x, float x_min, float x_max, int bits);
void CAN_Unpack_Command(const uint8_t* data, CAN_Command_t* cmd);
void CAN_Pack_Feedback(uint8_t* data, const CAN_Feedback_t* fb);
/* USER CODE END PFP */

int main(void)
{

  /* MCU Configuration--------------------------------------------------------*/

  /* Reset of all peripherals, Initializes the Flash interface and the Systick. */
  HAL_Init();

  /* Configure the system clock */
  SystemClock_Config();

  /* Initialize all configured peripherals */
  MX_GPIO_Init();
  MX_DMA_Init();
  MX_ADC1_Init();
  MX_ADC2_Init();
  MX_CORDIC_Init();
  MX_I2C3_Init();
  MX_OPAMP1_Init();
  MX_OPAMP2_Init();
  MX_TIM1_Init();
  MX_TIM4_Init();
  MX_USART1_UART_Init();
  MX_MotorControl_Init();
  MX_FDCAN1_Init();

  /* Initialize interrupts */
  MX_NVIC_Init();
  /* USER CODE BEGIN 2 */

  /* Read IDENTITY strap (PC13) to determine motor ID.
   * MX configures PC13 as input with internal pull-up.
   * Floating → reads HIGH → ID 0x01
   * Shorted to GND → reads LOW → ID 0x02 */
  if (HAL_GPIO_ReadPin(IDENTITY_GPIO_Port, IDENTITY_Pin) == GPIO_PIN_RESET)
    g_motor_id = 0x02;
  else
    g_motor_id = 0x01;
  g_ctrl_id = g_motor_id + 0x200;

  CAN_Interrupt_Init();

    HAL_Delay(500);//let things start
    MC_AcknowledgeFaultMotor1();
    MC_ProgramTorqueRampMotor1(0,0);
    MC_StartMotor1();
    while(MC_GetSTMStateMotor1() != RUN){
  	  HAL_GPIO_TogglePin(LED_GPIO_Port, LED_Pin);
  	  HAL_Delay(200);
    }
    //  while(MC_GetAlignmentStatusMotor1() != TC_ALIGNMENT_COMPLETED){
    //	  //wait
    //  } for pos control only

//    MC_StartMotor1();
//    HAL_Delay(500);
//    MC_AcknowledgeFaultMotor1();
//    MC_StopMotor1();
//    HAL_Delay(500);
//    MC_StartMotor1();
  /* USER CODE END 2 */

  /* Infinite loop */
  while (1)
  {

    /* USER CODE BEGIN 3 */
#if (TEMP_TORQUE_RAMP_TEST_ENABLE == 1U)
    static uint8_t torque_test_phase = 0U;
    static uint32_t torque_test_phase_start_ms = 0U;
    uint32_t torque_test_now_ms = HAL_GetTick();

    if (MC_GetSTMStateMotor1() != RUN)
    {
      torque_test_phase = 0U;
    }
    else if (torque_test_phase == 0U)
    {
      MC_ProgramTorqueRampMotor1_F(TEMP_TORQUE_TEST_NM / MOTOR_KT,
                                   TEMP_TORQUE_RAMP_MS);
      HAL_GPIO_TogglePin(LED_GPIO_Port, LED_Pin);
      torque_test_phase_start_ms = torque_test_now_ms;
      torque_test_phase = 1U;
    }
    else if ((uint32_t)(torque_test_now_ms - torque_test_phase_start_ms) >=
             (TEMP_TORQUE_RAMP_MS + TEMP_TORQUE_HOLD_MS))
    {
      float torque_nm = (torque_test_phase == 1U) ?
                        -TEMP_TORQUE_TEST_NM : TEMP_TORQUE_TEST_NM;
      MC_ProgramTorqueRampMotor1_F(torque_nm / MOTOR_KT,
                                   TEMP_TORQUE_RAMP_MS);
      HAL_GPIO_TogglePin(LED_GPIO_Port, LED_Pin);
      torque_test_phase_start_ms = torque_test_now_ms;
      torque_test_phase = (torque_test_phase == 1U) ? 2U : 1U;
    }
#endif

    /* ---- Force-realign handler ----------------------------------------
     * CMD_FORCE_ALIGN: stop motor → clear EncAligned → restart.
     * Three-phase state machine so we can wait for IDLE between steps. */
    if (force_align)
    {
      MCI_State_t st = MC_GetSTMStateMotor1();

      if (st == RUN || st == IDLE || st == FAULT_OVER || st == STOP)
      {
        if (st == RUN)
        {
          MC_StopMotor1();                        /* phase 1: request stop */
        }
        else if (st == FAULT_OVER)
        {
          MC_AcknowledgeFaultMotor1();            /* clear any fault */
        }
        else if (st == IDLE)
        {
          /* Phase 2: reset aligned flag so CHARGE_BOOT_CAP runs alignment */
          EncAlignCtrlM1.EncAligned = false;
          MC_ProgramTorqueRampMotor1(0, 0);
          MC_StartMotor1();
          force_align = 0;                        /* done */
        }
        /* if STOP, just wait — will become IDLE */
      }
    }
  }
  /* USER CODE END 3 */
}

void SystemClock_Config(void)
{
  RCC_OscInitTypeDef RCC_OscInitStruct = {0};
  RCC_ClkInitTypeDef RCC_ClkInitStruct = {0};

  /** Configure the main internal regulator output voltage
  */
  HAL_PWREx_ControlVoltageScaling(PWR_REGULATOR_VOLTAGE_SCALE1);

  /** Initializes the RCC Oscillators according to the specified parameters
  * in the RCC_OscInitTypeDef structure.
  */
  RCC_OscInitStruct.OscillatorType = RCC_OSCILLATORTYPE_HSI;
  RCC_OscInitStruct.HSIState = RCC_HSI_ON;
  RCC_OscInitStruct.HSICalibrationValue = RCC_HSICALIBRATION_DEFAULT;
  RCC_OscInitStruct.PLL.PLLState = RCC_PLL_ON;
  RCC_OscInitStruct.PLL.PLLSource = RCC_PLLSOURCE_HSI;
  RCC_OscInitStruct.PLL.PLLM = RCC_PLLM_DIV1;
  RCC_OscInitStruct.PLL.PLLN = 10;
  RCC_OscInitStruct.PLL.PLLP = RCC_PLLP_DIV4;
  RCC_OscInitStruct.PLL.PLLQ = RCC_PLLQ_DIV2;
  RCC_OscInitStruct.PLL.PLLR = RCC_PLLR_DIV2;
  if (HAL_RCC_OscConfig(&RCC_OscInitStruct) != HAL_OK)
  {
    Error_Handler();
  }

  /** Initializes the CPU, AHB and APB buses clocks
  */
  RCC_ClkInitStruct.ClockType = RCC_CLOCKTYPE_HCLK|RCC_CLOCKTYPE_SYSCLK
                              |RCC_CLOCKTYPE_PCLK1|RCC_CLOCKTYPE_PCLK2;
  RCC_ClkInitStruct.SYSCLKSource = RCC_SYSCLKSOURCE_PLLCLK;
  RCC_ClkInitStruct.AHBCLKDivider = RCC_SYSCLK_DIV1;
  RCC_ClkInitStruct.APB1CLKDivider = RCC_HCLK_DIV1;
  RCC_ClkInitStruct.APB2CLKDivider = RCC_HCLK_DIV1;

  if (HAL_RCC_ClockConfig(&RCC_ClkInitStruct, FLASH_LATENCY_2) != HAL_OK)
  {
    Error_Handler();
  }
}

/**
  * @brief NVIC Configuration.
  * @retval None
  */
static void MX_NVIC_Init(void)
{
  /* USART1_IRQn interrupt configuration */
  HAL_NVIC_SetPriority(USART1_IRQn, 3, 1);
  HAL_NVIC_EnableIRQ(USART1_IRQn);
  /* DMA1_Channel1_IRQn interrupt configuration */
  HAL_NVIC_SetPriority(DMA1_Channel1_IRQn, 3, 0);
  HAL_NVIC_EnableIRQ(DMA1_Channel1_IRQn);
  /* TIM1_BRK_TIM15_IRQn interrupt configuration */
  HAL_NVIC_SetPriority(TIM1_BRK_TIM15_IRQn, 4, 1);
  HAL_NVIC_EnableIRQ(TIM1_BRK_TIM15_IRQn);
  /* TIM1_UP_TIM16_IRQn interrupt configuration */
  HAL_NVIC_SetPriority(TIM1_UP_TIM16_IRQn, 0, 0);
  HAL_NVIC_EnableIRQ(TIM1_UP_TIM16_IRQn);
  /* ADC1_2_IRQn interrupt configuration */
  HAL_NVIC_SetPriority(ADC1_2_IRQn, 2, 0);
  HAL_NVIC_EnableIRQ(ADC1_2_IRQn);
  /* TIM4_IRQn interrupt configuration */
  HAL_NVIC_SetPriority(TIM4_IRQn, 3, 0);
  HAL_NVIC_EnableIRQ(TIM4_IRQn);
}

static void MX_ADC1_Init(void)
{

  ADC_MultiModeTypeDef multimode = {0};
  ADC_InjectionConfTypeDef sConfigInjected = {0};
  ADC_ChannelConfTypeDef sConfig = {0};

  /** Common config
  */
  hadc1.Instance = ADC1;
  hadc1.Init.ClockPrescaler = ADC_CLOCK_ASYNC_DIV1;
  hadc1.Init.Resolution = ADC_RESOLUTION_12B;
  hadc1.Init.DataAlign = ADC_DATAALIGN_LEFT;
  hadc1.Init.GainCompensation = 0;
  hadc1.Init.ScanConvMode = ADC_SCAN_DISABLE;
  hadc1.Init.EOCSelection = ADC_EOC_SINGLE_CONV;
  hadc1.Init.LowPowerAutoWait = DISABLE;
  hadc1.Init.ContinuousConvMode = DISABLE;
  hadc1.Init.NbrOfConversion = 1;
  hadc1.Init.DiscontinuousConvMode = DISABLE;
  hadc1.Init.ExternalTrigConv = ADC_SOFTWARE_START;
  hadc1.Init.ExternalTrigConvEdge = ADC_EXTERNALTRIGCONVEDGE_NONE;
  hadc1.Init.DMAContinuousRequests = DISABLE;
  hadc1.Init.Overrun = ADC_OVR_DATA_PRESERVED;
  hadc1.Init.OversamplingMode = DISABLE;
  if (HAL_ADC_Init(&hadc1) != HAL_OK)
  {
    Error_Handler();
  }

  /** Configure the ADC multi-mode
  */
  multimode.Mode = ADC_MODE_INDEPENDENT;
  if (HAL_ADCEx_MultiModeConfigChannel(&hadc1, &multimode) != HAL_OK)
  {
    Error_Handler();
  }

  /** Configure Injected Channel
  */
  sConfigInjected.InjectedChannel = ADC_CHANNEL_3;
  sConfigInjected.InjectedRank = ADC_INJECTED_RANK_1;
  sConfigInjected.InjectedSamplingTime = ADC_SAMPLETIME_6CYCLES_5;
  sConfigInjected.InjectedSingleDiff = ADC_SINGLE_ENDED;
  sConfigInjected.InjectedOffsetNumber = ADC_OFFSET_NONE;
  sConfigInjected.InjectedOffset = 0;
  sConfigInjected.InjectedNbrOfConversion = 1;
  sConfigInjected.InjectedDiscontinuousConvMode = DISABLE;
  sConfigInjected.AutoInjectedConv = DISABLE;
  sConfigInjected.QueueInjectedContext = DISABLE;
  sConfigInjected.ExternalTrigInjecConv = ADC_EXTERNALTRIGINJEC_T1_TRGO;
  sConfigInjected.ExternalTrigInjecConvEdge = ADC_EXTERNALTRIGINJECCONV_EDGE_RISING;
  sConfigInjected.InjecOversamplingMode = DISABLE;
  if (HAL_ADCEx_InjectedConfigChannel(&hadc1, &sConfigInjected) != HAL_OK)
  {
    Error_Handler();
  }

  /** Configure Regular Channel
  */
  sConfig.Channel = ADC_CHANNEL_1;
  sConfig.Rank = ADC_REGULAR_RANK_1;
  sConfig.SamplingTime = ADC_SAMPLETIME_47CYCLES_5;
  sConfig.SingleDiff = ADC_SINGLE_ENDED;
  sConfig.OffsetNumber = ADC_OFFSET_NONE;
  sConfig.Offset = 0;
  if (HAL_ADC_ConfigChannel(&hadc1, &sConfig) != HAL_OK)
  {
    Error_Handler();
  }

}

static void MX_ADC2_Init(void)
{

  ADC_InjectionConfTypeDef sConfigInjected = {0};
  ADC_ChannelConfTypeDef sConfig = {0};

  /** Common config
  */
  hadc2.Instance = ADC2;
  hadc2.Init.ClockPrescaler = ADC_CLOCK_ASYNC_DIV1;
  hadc2.Init.Resolution = ADC_RESOLUTION_12B;
  hadc2.Init.DataAlign = ADC_DATAALIGN_LEFT;
  hadc2.Init.GainCompensation = 0;
  hadc2.Init.ScanConvMode = ADC_SCAN_DISABLE;
  hadc2.Init.EOCSelection = ADC_EOC_SINGLE_CONV;
  hadc2.Init.LowPowerAutoWait = DISABLE;
  hadc2.Init.ContinuousConvMode = DISABLE;
  hadc2.Init.NbrOfConversion = 1;
  hadc2.Init.DiscontinuousConvMode = DISABLE;
  hadc2.Init.ExternalTrigConv = ADC_SOFTWARE_START;
  hadc2.Init.ExternalTrigConvEdge = ADC_EXTERNALTRIGCONVEDGE_NONE;
  hadc2.Init.DMAContinuousRequests = DISABLE;
  hadc2.Init.Overrun = ADC_OVR_DATA_PRESERVED;
  hadc2.Init.OversamplingMode = DISABLE;
  if (HAL_ADC_Init(&hadc2) != HAL_OK)
  {
    Error_Handler();
  }

  /** Configure Injected Channel
  */
  sConfigInjected.InjectedChannel = ADC_CHANNEL_3;
  sConfigInjected.InjectedRank = ADC_INJECTED_RANK_1;
  sConfigInjected.InjectedSamplingTime = ADC_SAMPLETIME_6CYCLES_5;
  sConfigInjected.InjectedSingleDiff = ADC_SINGLE_ENDED;
  sConfigInjected.InjectedOffsetNumber = ADC_OFFSET_NONE;
  sConfigInjected.InjectedOffset = 0;
  sConfigInjected.InjectedNbrOfConversion = 1;
  sConfigInjected.InjectedDiscontinuousConvMode = DISABLE;
  sConfigInjected.AutoInjectedConv = DISABLE;
  sConfigInjected.QueueInjectedContext = DISABLE;
  sConfigInjected.ExternalTrigInjecConv = ADC_EXTERNALTRIGINJEC_T1_TRGO;
  sConfigInjected.ExternalTrigInjecConvEdge = ADC_EXTERNALTRIGINJECCONV_EDGE_RISING;
  sConfigInjected.InjecOversamplingMode = DISABLE;
  if (HAL_ADCEx_InjectedConfigChannel(&hadc2, &sConfigInjected) != HAL_OK)
  {
    Error_Handler();
  }

  /** Configure Regular Channel
  */
  sConfig.Channel = ADC_CHANNEL_5;
  sConfig.Rank = ADC_REGULAR_RANK_1;
  sConfig.SamplingTime = ADC_SAMPLETIME_47CYCLES_5;
  sConfig.SingleDiff = ADC_SINGLE_ENDED;
  sConfig.OffsetNumber = ADC_OFFSET_NONE;
  sConfig.Offset = 0;
  if (HAL_ADC_ConfigChannel(&hadc2, &sConfig) != HAL_OK)
  {
    Error_Handler();
  }

}

static void MX_CORDIC_Init(void)
{

  hcordic.Instance = CORDIC;
  if (HAL_CORDIC_Init(&hcordic) != HAL_OK)
  {
    Error_Handler();
  }

}

static void MX_FDCAN1_Init(void)
{

  hfdcan1.Instance = FDCAN1;
  hfdcan1.Init.ClockDivider = FDCAN_CLOCK_DIV1;
  hfdcan1.Init.FrameFormat = FDCAN_FRAME_CLASSIC;
  hfdcan1.Init.Mode = FDCAN_MODE_NORMAL;
  hfdcan1.Init.AutoRetransmission = DISABLE;
  hfdcan1.Init.TransmitPause = DISABLE;
  hfdcan1.Init.ProtocolException = DISABLE;
  hfdcan1.Init.NominalPrescaler = 5;
  hfdcan1.Init.NominalSyncJumpWidth = 1;
  hfdcan1.Init.NominalTimeSeg1 = 12;
  hfdcan1.Init.NominalTimeSeg2 = 3;
  hfdcan1.Init.DataPrescaler = 1;
  hfdcan1.Init.DataSyncJumpWidth = 1;
  hfdcan1.Init.DataTimeSeg1 = 1;
  hfdcan1.Init.DataTimeSeg2 = 1;
  hfdcan1.Init.StdFiltersNbr = 0;
  hfdcan1.Init.ExtFiltersNbr = 0;
  hfdcan1.Init.TxFifoQueueMode = FDCAN_TX_FIFO_OPERATION;
  if (HAL_FDCAN_Init(&hfdcan1) != HAL_OK)
  {
    Error_Handler();
  }

}

static void MX_I2C3_Init(void)
{

  hi2c3.Instance = I2C3;
  hi2c3.Init.Timing = 0x00B10E24;
  hi2c3.Init.OwnAddress1 = 0;
  hi2c3.Init.AddressingMode = I2C_ADDRESSINGMODE_7BIT;
  hi2c3.Init.DualAddressMode = I2C_DUALADDRESS_DISABLE;
  hi2c3.Init.OwnAddress2 = 0;
  hi2c3.Init.OwnAddress2Masks = I2C_OA2_NOMASK;
  hi2c3.Init.GeneralCallMode = I2C_GENERALCALL_DISABLE;
  hi2c3.Init.NoStretchMode = I2C_NOSTRETCH_DISABLE;
  if (HAL_I2C_Init(&hi2c3) != HAL_OK)
  {
    Error_Handler();
  }

  /** Configure Analogue filter
  */
  if (HAL_I2CEx_ConfigAnalogFilter(&hi2c3, I2C_ANALOGFILTER_ENABLE) != HAL_OK)
  {
    Error_Handler();
  }

  /** Configure Digital filter
  */
  if (HAL_I2CEx_ConfigDigitalFilter(&hi2c3, 0) != HAL_OK)
  {
    Error_Handler();
  }

  /** I2C Fast mode Plus enable
  */
  HAL_I2CEx_EnableFastModePlus(I2C_FASTMODEPLUS_I2C3);

}

static void MX_OPAMP1_Init(void)
{

  hopamp1.Instance = OPAMP1;
  hopamp1.Init.PowerMode = OPAMP_POWERMODE_NORMALSPEED;
  hopamp1.Init.Mode = OPAMP_STANDALONE_MODE;
  hopamp1.Init.InvertingInput = OPAMP_INVERTINGINPUT_IO0;
  hopamp1.Init.NonInvertingInput = OPAMP_NONINVERTINGINPUT_IO0;
  hopamp1.Init.InternalOutput = DISABLE;
  hopamp1.Init.TimerControlledMuxmode = OPAMP_TIMERCONTROLLEDMUXMODE_DISABLE;
  hopamp1.Init.UserTrimming = OPAMP_TRIMMING_FACTORY;
  if (HAL_OPAMP_Init(&hopamp1) != HAL_OK)
  {
    Error_Handler();
  }

}

static void MX_OPAMP2_Init(void)
{

  hopamp2.Instance = OPAMP2;
  hopamp2.Init.PowerMode = OPAMP_POWERMODE_NORMALSPEED;
  hopamp2.Init.Mode = OPAMP_STANDALONE_MODE;
  hopamp2.Init.InvertingInput = OPAMP_INVERTINGINPUT_IO1;
  hopamp2.Init.NonInvertingInput = OPAMP_NONINVERTINGINPUT_IO2;
  hopamp2.Init.InternalOutput = DISABLE;
  hopamp2.Init.TimerControlledMuxmode = OPAMP_TIMERCONTROLLEDMUXMODE_DISABLE;
  hopamp2.Init.UserTrimming = OPAMP_TRIMMING_FACTORY;
  if (HAL_OPAMP_Init(&hopamp2) != HAL_OK)
  {
    Error_Handler();
  }

}

static void MX_TIM1_Init(void)
{

  TIM_MasterConfigTypeDef sMasterConfig = {0};
  TIM_OC_InitTypeDef sConfigOC = {0};
  TIM_BreakDeadTimeConfigTypeDef sBreakDeadTimeConfig = {0};

  htim1.Instance = TIM1;
  htim1.Init.Prescaler = ((TIM_CLOCK_DIVIDER) - 1);
  htim1.Init.CounterMode = TIM_COUNTERMODE_CENTERALIGNED1;
  htim1.Init.Period = ((PWM_PERIOD_CYCLES) / 2);
  htim1.Init.ClockDivision = TIM_CLOCKDIVISION_DIV2;
  htim1.Init.RepetitionCounter = (REP_COUNTER);
  htim1.Init.AutoReloadPreload = TIM_AUTORELOAD_PRELOAD_DISABLE;
  if (HAL_TIM_PWM_Init(&htim1) != HAL_OK)
  {
    Error_Handler();
  }
  sMasterConfig.MasterOutputTrigger = TIM_TRGO_OC4REF;
  sMasterConfig.MasterOutputTrigger2 = TIM_TRGO2_RESET;
  sMasterConfig.MasterSlaveMode = TIM_MASTERSLAVEMODE_DISABLE;
  if (HAL_TIMEx_MasterConfigSynchronization(&htim1, &sMasterConfig) != HAL_OK)
  {
    Error_Handler();
  }
  sConfigOC.OCMode = TIM_OCMODE_PWM1;
  sConfigOC.Pulse = ((PWM_PERIOD_CYCLES) / 4);
  sConfigOC.OCPolarity = TIM_OCPOLARITY_HIGH;
  sConfigOC.OCNPolarity = TIM_OCNPOLARITY_HIGH;
  sConfigOC.OCFastMode = TIM_OCFAST_DISABLE;
  sConfigOC.OCIdleState = TIM_OCIDLESTATE_RESET;
  sConfigOC.OCNIdleState = TIM_OCNIDLESTATE_RESET;
  if (HAL_TIM_PWM_ConfigChannel(&htim1, &sConfigOC, TIM_CHANNEL_1) != HAL_OK)
  {
    Error_Handler();
  }
  if (HAL_TIM_PWM_ConfigChannel(&htim1, &sConfigOC, TIM_CHANNEL_2) != HAL_OK)
  {
    Error_Handler();
  }
  if (HAL_TIM_PWM_ConfigChannel(&htim1, &sConfigOC, TIM_CHANNEL_3) != HAL_OK)
  {
    Error_Handler();
  }
  sConfigOC.OCMode = TIM_OCMODE_PWM2;
  sConfigOC.Pulse = (((PWM_PERIOD_CYCLES) / 2) - (HTMIN));
  if (HAL_TIM_PWM_ConfigChannel(&htim1, &sConfigOC, TIM_CHANNEL_4) != HAL_OK)
  {
    Error_Handler();
  }
  sBreakDeadTimeConfig.OffStateRunMode = TIM_OSSR_ENABLE;
  sBreakDeadTimeConfig.OffStateIDLEMode = TIM_OSSI_ENABLE;
  sBreakDeadTimeConfig.LockLevel = TIM_LOCKLEVEL_OFF;
  sBreakDeadTimeConfig.DeadTime = ((DEAD_TIME_COUNTS) / 2);
  sBreakDeadTimeConfig.BreakState = TIM_BREAK_DISABLE;
  sBreakDeadTimeConfig.BreakPolarity = TIM_BREAKPOLARITY_HIGH;
  sBreakDeadTimeConfig.BreakFilter = 0;
  sBreakDeadTimeConfig.BreakAFMode = TIM_BREAK_AFMODE_INPUT;
  sBreakDeadTimeConfig.Break2State = TIM_BREAK2_DISABLE;
  sBreakDeadTimeConfig.Break2Polarity = TIM_BREAK2POLARITY_HIGH;
  sBreakDeadTimeConfig.Break2Filter = 3;
  sBreakDeadTimeConfig.Break2AFMode = TIM_BREAK_AFMODE_INPUT;
  sBreakDeadTimeConfig.AutomaticOutput = TIM_AUTOMATICOUTPUT_DISABLE;
  if (HAL_TIMEx_ConfigBreakDeadTime(&htim1, &sBreakDeadTimeConfig) != HAL_OK)
  {
    Error_Handler();
  }
  HAL_TIM_MspPostInit(&htim1);

}

static void MX_TIM4_Init(void)
{

  TIM_Encoder_InitTypeDef sConfig = {0};
  TIM_MasterConfigTypeDef sMasterConfig = {0};

  htim4.Instance = TIM4;
  htim4.Init.Prescaler = 0;
  htim4.Init.CounterMode = TIM_COUNTERMODE_UP;
  htim4.Init.Period = M1_PULSE_NBR;
  htim4.Init.ClockDivision = TIM_CLOCKDIVISION_DIV1;
  htim4.Init.AutoReloadPreload = TIM_AUTORELOAD_PRELOAD_DISABLE;
  sConfig.EncoderMode = TIM_ENCODERMODE_TI12;
  sConfig.IC1Polarity = TIM_ICPOLARITY_RISING;
  sConfig.IC1Selection = TIM_ICSELECTION_DIRECTTI;
  sConfig.IC1Prescaler = TIM_ICPSC_DIV1;
  sConfig.IC1Filter = M1_ENC_IC_FILTER;
  sConfig.IC2Polarity = TIM_ICPOLARITY_FALLING;
  sConfig.IC2Selection = TIM_ICSELECTION_DIRECTTI;
  sConfig.IC2Prescaler = TIM_ICPSC_DIV1;
  sConfig.IC2Filter = M1_ENC_IC_FILTER;
  if (HAL_TIM_Encoder_Init(&htim4, &sConfig) != HAL_OK)
  {
    Error_Handler();
  }
  sMasterConfig.MasterOutputTrigger = TIM_TRGO_RESET;
  sMasterConfig.MasterSlaveMode = TIM_MASTERSLAVEMODE_DISABLE;
  if (HAL_TIMEx_MasterConfigSynchronization(&htim4, &sMasterConfig) != HAL_OK)
  {
    Error_Handler();
  }

}

static void MX_USART1_UART_Init(void)
{

  huart1.Instance = USART1;
  huart1.Init.BaudRate = 115200;
  huart1.Init.WordLength = UART_WORDLENGTH_8B;
  huart1.Init.StopBits = UART_STOPBITS_1;
  huart1.Init.Parity = UART_PARITY_NONE;
  huart1.Init.Mode = UART_MODE_TX_RX;
  huart1.Init.HwFlowCtl = UART_HWCONTROL_NONE;
  huart1.Init.OverSampling = UART_OVERSAMPLING_16;
  huart1.Init.OneBitSampling = UART_ONE_BIT_SAMPLE_DISABLE;
  huart1.Init.ClockPrescaler = UART_PRESCALER_DIV1;
  huart1.AdvancedInit.AdvFeatureInit = UART_ADVFEATURE_NO_INIT;
  if (HAL_UART_Init(&huart1) != HAL_OK)
  {
    Error_Handler();
  }
  if (HAL_UARTEx_SetTxFifoThreshold(&huart1, UART_TXFIFO_THRESHOLD_1_8) != HAL_OK)
  {
    Error_Handler();
  }
  if (HAL_UARTEx_SetRxFifoThreshold(&huart1, UART_RXFIFO_THRESHOLD_1_8) != HAL_OK)
  {
    Error_Handler();
  }
  if (HAL_UARTEx_DisableFifoMode(&huart1) != HAL_OK)
  {
    Error_Handler();
  }

}

static void MX_DMA_Init(void)
{

  /* DMA controller clock enable */
  __HAL_RCC_DMAMUX1_CLK_ENABLE();
  __HAL_RCC_DMA1_CLK_ENABLE();

}

static void MX_GPIO_Init(void)
{
  GPIO_InitTypeDef GPIO_InitStruct = {0};

  /* GPIO Ports Clock Enable */
  __HAL_RCC_GPIOC_CLK_ENABLE();
  __HAL_RCC_GPIOA_CLK_ENABLE();
  __HAL_RCC_GPIOB_CLK_ENABLE();
  __HAL_RCC_GPIOE_CLK_ENABLE();

  /*Configure GPIO pin Output Level */
  HAL_GPIO_WritePin(GD_WAKE_GPIO_Port, GD_WAKE_Pin, GPIO_PIN_SET);

  /*Configure GPIO pin Output Level */
  HAL_GPIO_WritePin(LED_GPIO_Port, LED_Pin, GPIO_PIN_RESET);

  /*Configure GPIO pin : IDENTITY_Pin */
  GPIO_InitStruct.Pin = IDENTITY_Pin;
  GPIO_InitStruct.Mode = GPIO_MODE_INPUT;
  GPIO_InitStruct.Pull = GPIO_PULLUP;
  HAL_GPIO_Init(IDENTITY_GPIO_Port, &GPIO_InitStruct);

  /*Configure GPIO pin : GD_WAKE_Pin */
  GPIO_InitStruct.Pin = GD_WAKE_Pin;
  GPIO_InitStruct.Mode = GPIO_MODE_OUTPUT_PP;
  GPIO_InitStruct.Pull = GPIO_NOPULL;
  GPIO_InitStruct.Speed = GPIO_SPEED_FREQ_LOW;
  HAL_GPIO_Init(GD_WAKE_GPIO_Port, &GPIO_InitStruct);

  /*Configure GPIO pins : GD_READY_Pin GD_NFAULT_Pin */
  GPIO_InitStruct.Pin = GD_READY_Pin|GD_NFAULT_Pin;
  GPIO_InitStruct.Mode = GPIO_MODE_INPUT;
  GPIO_InitStruct.Pull = GPIO_PULLUP;
  HAL_GPIO_Init(GPIOE, &GPIO_InitStruct);

  /*Configure GPIO pin : LED_Pin */
  GPIO_InitStruct.Pin = LED_Pin;
  GPIO_InitStruct.Mode = GPIO_MODE_OUTPUT_PP;
  GPIO_InitStruct.Pull = GPIO_NOPULL;
  GPIO_InitStruct.Speed = GPIO_SPEED_FREQ_LOW;
  HAL_GPIO_Init(LED_GPIO_Port, &GPIO_InitStruct);

}

/* USER CODE BEGIN 4 */

/**
 * @brief Override the MCSDK medium-frequency hook (runs at 1 kHz) to apply
 *        the full impedance-control torque command to the motor.
 *        τ = kp*(p_ref - p) + kd*(v_ref - v) + τ_ff
 */
void MC_APP_PostMediumFrequencyHook_M1(void)
{
#if (TEMP_TORQUE_RAMP_TEST_ENABLE == 1U)
    return;
#endif

    /* Only run the impedance controller when the motor is actually spinning.
     * In FAULT_NOW / FAULT_OVER / IDLE etc. skip the torque command so that
     * stale targets don't get replayed the moment the motor is restarted. */
    if (MC_GetSTMStateMotor1() != RUN)
        return;

    /* 1. Current mechanical position (rad), converted from s16degrees format
     * s16degrees: -32768 = -π rad, +32767 = +π rad (wraps each revolution) */
    float pos_actual = (float)ENCODER_M1._Super.hMecAngle * ((float)M_PI / 32768.0f);

    /* 2. Current mechanical velocity (rad/s) — sign must match positive direction convention */
    float vel_actual = ENCODER_VEL_SIGN * MC_GetAverageMecSpeedMotor1_F() * RPM_TO_RADS;

    /* 3. Full impedance torque (Nm) */
    float tau = ImpedanceCtrl.kp * (ImpedanceCtrl.position_target - pos_actual)
              + ImpedanceCtrl.kd * (ImpedanceCtrl.velocity_target - vel_actual)
              + ImpedanceCtrl.torque_target;

    /* 4. Clamp to physical torque limit (IQMAX_A × KT = 0.19 Nm) */
    if (tau >  TORQUE_MAX_NM) tau =  TORQUE_MAX_NM;
    if (tau < -TORQUE_MAX_NM) tau = -TORQUE_MAX_NM;

    /* 5. Convert Nm -> Iq (A) and apply immediately (duration = 0 ms) */
    MC_ProgramTorqueRampMotor1_F(tau / MOTOR_KT, 0);
}

void CAN_Unpack_Command(const uint8_t* data, CAN_Command_t* cmd) {
    // Define the exact hardcoded boundaries used by your main controller
    const float P_MIN = -(float)M_PI;  const float P_MAX = (float)M_PI;
    const float V_MIN = -45.0f;  const float V_MAX = 45.0f;
    const float KP_MIN = 0.0f;   const float KP_MAX = 500.0f;
    const float KD_MIN = 0.0f;   const float KD_MAX = 15.0f;
    const float Torque_MIN = -TORQUE_MAX_NM;  const float Torque_MAX = TORQUE_MAX_NM;

    // 1. Reconstruct integers from the byte stream
    uint16_t p_int  = (data[0] << 8) | data[1];
    uint16_t v_int  = (data[2] << 4) | (data[3] >> 4);
    uint16_t kp_int = ((data[3] & 0x0F) << 8) | data[4];
    uint16_t kd_int = (data[5] << 4) | (data[6] >> 4);
    uint16_t t_int  = ((data[6] & 0x0F) << 8) | data[7];

    // 2. Convert integers back to physical float values
    cmd->position_target = Math_Map_Int_To_Float(p_int,  P_MIN,  P_MAX,  16);
    cmd->velocity_target = Math_Map_Int_To_Float(v_int,  V_MIN,  V_MAX,  12);
    cmd->kp              = Math_Map_Int_To_Float(kp_int, KP_MIN, KP_MAX, 12);
    cmd->kd              = Math_Map_Int_To_Float(kd_int, KD_MIN, KD_MAX, 12);
    cmd->torque_ff       = Math_Map_Int_To_Float(t_int,  Torque_MIN,  Torque_MAX,  12);
}

// Helper function to map floats to integers
int Math_Map_Float_To_Int(float x, float x_min, float x_max, int bits) {
    if (x < x_min) x = x_min;
    if (x > x_max) x = x_max;
    float total_intervals = (float)((1 << bits) - 1);
    return (int)((x - x_min) * total_intervals / (x_max - x_min));
}
float Math_Map_Int_To_Float(int x_int, float x_min, float x_max, int bits) {
    float total_intervals = (float)((1 << bits) - 1);
    return x_min + ((float)x_int * (x_max - x_min) / total_intervals);
}

void CAN_Pack_Feedback(uint8_t* data, const CAN_Feedback_t* fb) {
    const float P_MIN = -(float)M_PI; const float P_MAX = (float)M_PI;
    const float V_MIN = -1500.0f; const float V_MAX = 1500.0f;
    const float Torque_MIN = -TORQUE_MAX_NM; const float Torque_MAX = TORQUE_MAX_NM;

    // Convert actual variables to integers
    uint16_t p_int = Math_Map_Float_To_Int(fb->position_actual, P_MIN, P_MAX, 16);
    uint16_t v_int = Math_Map_Float_To_Int(fb->velocity_actual, V_MIN, V_MAX, 16);
    uint16_t t_int = Math_Map_Float_To_Int(fb->torque_actual,   Torque_MIN, Torque_MAX, 16);

    // Stuff integers into the 8-byte array
    // data[0]: upper nibble = compressed state, lower nibble = motor_id
    //   0=IDLE  1=RUN  2=STOP  3=FAULT_NOW  4=FAULT_OVER  5=other
    MCI_State_t st = MC_GetSTMStateMotor1();
    uint8_t state_nibble;
    switch (st) {
        case IDLE:             state_nibble = 0; break;
        case RUN:              state_nibble = 1; break;
        case STOP:             state_nibble = 2; break;
        case FAULT_NOW:        state_nibble = 3; break;
        case FAULT_OVER:       state_nibble = 4; break;
        default:               state_nibble = 5; break;
    }
    data[0] = (state_nibble << 4) | (fb->motor_id & 0x0F);
    data[1] = fb->error_code;

    data[2] = (p_int >> 8) & 0xFF;
    data[3] = p_int & 0xFF;

    data[4] = (v_int >> 8) & 0xFF;
    data[5] = v_int & 0xFF;

    data[6] = (t_int >> 8) & 0xFF;
    data[7] = t_int & 0xFF;
}

void CAN_Interrupt_Init(void)
  {
      FDCAN_FilterTypeDef filterConfig;

      // 1. Configure the FDCAN filter profile to ACCEPT EVERYTHING for debugging
      filterConfig.IdType = FDCAN_STANDARD_ID;
      filterConfig.FilterIndex = 0;
      filterConfig.FilterType = FDCAN_FILTER_RANGE;
      filterConfig.FilterConfig = FDCAN_FILTER_TO_RXFIFO0;
      filterConfig.FilterID1 = 0x000;
      filterConfig.FilterID2 = 0x7FF;

      if (HAL_FDCAN_ConfigFilter(&hfdcan1, &filterConfig) != HAL_OK)
      {
          Error_Handler();
      }

      // 2. Start the FDCAN Module Hardware
      if (HAL_FDCAN_Start(&hfdcan1) != HAL_OK)
      {
          Error_Handler();
      }

      // 3. Enable Interrupt Notifications for incoming messages on FIFO 0
      if (HAL_FDCAN_ActivateNotification(&hfdcan1, FDCAN_IT_RX_FIFO0_NEW_MESSAGE, 0) != HAL_OK)
      {
          Error_Handler();
      }
  }

void HAL_FDCAN_RxFifo0Callback(FDCAN_HandleTypeDef *hfdcan, uint32_t RxFifo0ITs)
{
    uint8_t addressed_frame = 0U;

    // Ensure the interrupt source was a new message arriving
    if ((RxFifo0ITs & FDCAN_IT_RX_FIFO0_NEW_MESSAGE) != RESET)
    {
        FDCAN_RxHeaderTypeDef rxHeader;
        uint8_t rxData[8];

        // 1. Fetch message from FDCAN hardware FIFO 0
        if (HAL_FDCAN_GetRxMessage(hfdcan, FDCAN_RX_FIFO0, &rxHeader, rxData) == HAL_OK)
        {
            can_rx_count++;

            // -----------------------------------------

            // 2. Verify incoming identity envelope
            if (rxHeader.Identifier == g_motor_id)
            {
                addressed_frame = 1U;
                /* Auto-recover from a latched fault:
                 * FAULT_OVER means the fault condition has cleared but the
                 * state machine is waiting for an explicit acknowledgment.
                 * Zero the torque target first so the hook doesn't replay a
                 * large command the instant the motor restarts. */
                if (MC_GetSTMStateMotor1() == FAULT_OVER)
                {
                    ImpedanceCtrl.torque_target   = 0.0f;
                    ImpedanceCtrl.position_target = ImpedanceCtrl.position_curr;
                    ImpedanceCtrl.velocity_target = 0.0f;
                    ImpedanceCtrl.kp = 0.0f;
                    ImpedanceCtrl.kd = 0.0f;
                    MC_AcknowledgeFaultMotor1();
                }

                // Unpack payload data bytes
                CAN_Unpack_Command(rxData, &IncomingCmd);

                /* --- INTERPOLATION SETUP --- */
                __disable_irq();
                ImpedanceCtrl.position_target = IncomingCmd.position_target;
                ImpedanceCtrl.velocity_target = IncomingCmd.velocity_target;
                ImpedanceCtrl.torque_target   = IncomingCmd.torque_ff;
                ImpedanceCtrl.kp              = IncomingCmd.kp;
                ImpedanceCtrl.kd              = IncomingCmd.kd;

                ImpedanceCtrl.steps_per_can_frame = 20;
                ImpedanceCtrl.position_step = (ImpedanceCtrl.position_target - ImpedanceCtrl.position_curr) / 20.0f;
                ImpedanceCtrl.velocity_step = (ImpedanceCtrl.velocity_target - ImpedanceCtrl.velocity_curr) / 20.0f;
                ImpedanceCtrl.torque_step   = (ImpedanceCtrl.torque_target   - ImpedanceCtrl.torque_curr)   / 20.0f;
                ImpedanceCtrl.interpolation_counter = 0;
                __enable_irq();
            }

            /* --- STATE MACHINE CONTROL FRAME (CTRL_ID = 0x201) --- */
            else if (rxHeader.Identifier == g_ctrl_id && rxHeader.RxFrameType == FDCAN_DATA_FRAME
                     && rxHeader.DataLength == FDCAN_DLC_BYTES_1)
            {
                addressed_frame = 1U;
                if (rxData[0] == CMD_MOTOR_START)
                {
                    /* Acknowledge any latched fault before starting */
                    MC_AcknowledgeFaultMotor1();
                    /* Zero impedance targets so the hook starts from rest */
                    ImpedanceCtrl.torque_target   = 0.0f;
                    ImpedanceCtrl.position_target = ImpedanceCtrl.position_curr;
                    ImpedanceCtrl.velocity_target = 0.0f;
                    ImpedanceCtrl.kp = 0.0f;
                    ImpedanceCtrl.kd = 0.0f;
                    MC_StartMotor1();
                }
                else if (rxData[0] == CMD_MOTOR_STOP)
                {
                    MC_StopMotor1();
                }
                else if (rxData[0] == CMD_FORCE_ALIGN)
                {
                    /* Request realignment from main loop (can't block in ISR) */
                    force_align = 1;
                }
                else if (rxData[0] == CMD_FEEDBACK_REQUEST)
                {
                    /* Feedback is packed below without changing motor state. */
                }
                else
                {
                    addressed_frame = 0U;
                }
            }

            if (addressed_frame != 0U)
            {
                FDCAN_TxHeaderTypeDef txHeader;
                uint8_t txData[8];

                CurrentState.motor_id = g_motor_id;
                /* Use the sticky "occurred" register so the fault is visible even
                 * after the condition clears and the state has moved to FAULT_OVER.
                 * This register is only reset when MC_AcknowledgeFaultMotor1() is
                 * called (which happens automatically above on the next command). */
                CurrentState.error_code = (uint8_t)(MC_GetOccurredFaultsMotor1() & 0xFF);

                // 1. Fetch Angle: convert s16degrees → radians (-32768..+32767 = -π..+π)
                CurrentState.position_actual = (float)ENCODER_M1._Super.hMecAngle * ((float)M_PI / 32768.0f);

                // 2. Fetch speed (Returns RPM, convert to Rad/s)
                {
                    float speed_rpm = MC_GetAverageMecSpeedMotor1_F();
                    CurrentState.velocity_actual = ENCODER_VEL_SIGN * speed_rpm * RPM_TO_RADS;
                }

                // 3. Fetch Torque (Returns Iq in Amps, convert to Nm)
                {
                    qd_f_t current_qd = MC_GetIqdMotor1_F();
                    CurrentState.torque_actual = current_qd.q * MOTOR_KT;
                }

                CAN_Pack_Feedback(txData, &CurrentState);

                // Configure modern FDCAN transmission settings
                // We use standard response ID: MY_MOTOR_ID + 0x100 (e.g. 0x101)
                txHeader.Identifier = g_motor_id + 0x100;
                txHeader.IdType = FDCAN_STANDARD_ID;
                txHeader.TxFrameType = FDCAN_DATA_FRAME;
                txHeader.DataLength = FDCAN_DLC_BYTES_8;
                txHeader.ErrorStateIndicator = FDCAN_ESI_ACTIVE;
                txHeader.BitRateSwitch = FDCAN_BRS_OFF;
                txHeader.FDFormat = FDCAN_CLASSIC_CAN;
                txHeader.TxEventFifoControl = FDCAN_NO_TX_EVENTS;
                txHeader.MessageMarker = 0;

                // Fire payload back only for frames addressed to this node.
                HAL_FDCAN_AddMessageToTxFifoQ(hfdcan, &txHeader, txData);
            }
        }
    }
}

int _write(int fd, char* ptr, int len) {
  HAL_StatusTypeDef hstatus;

  if (fd == 1 || fd == 2) {
    hstatus = HAL_UART_Transmit(&huart1, (uint8_t *) ptr, len, 100);
    if (hstatus == HAL_OK)
      return len;
    else
      return -1;
  }
  return -1;
}
/* USER CODE END 4 */

void Error_Handler(void)
{
  __disable_irq();
  while (1)
  {
  }
}
